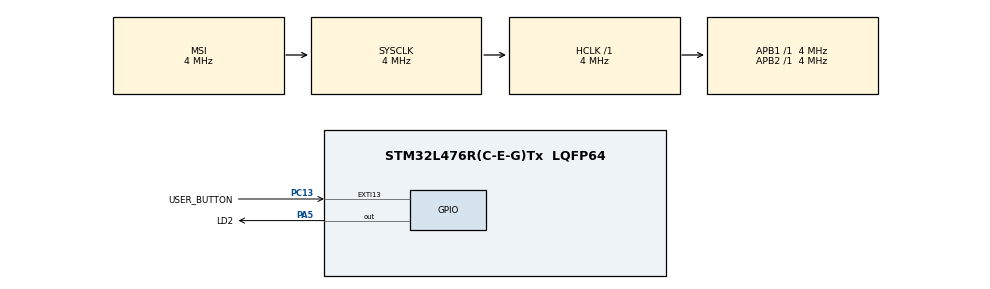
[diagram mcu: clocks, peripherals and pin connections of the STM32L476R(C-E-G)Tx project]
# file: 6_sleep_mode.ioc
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Mcu.Family=STM32L4
Mcu.Name=STM32L476R(C-E-G)Tx
Mcu.Package=LQFP64
NVIC.PriorityGroup=NVIC_PRIORITYGROUP_4
NVIC.RTC_WKUP_IRQn=true\:0\:0\:false\:false\:true\:true\:true\:true
PA13\ (JTMS-SWDIO).GPIO_Label=TMS
PA13\ (JTMS-SWDIO).Mode=Serial_Wire
PA13\ (JTMS-SWDIO).Signal=SYS_JTMS-SWDIO
PA14\ (JTCK-SWCLK).GPIO_Label=TCK
PA14\ (JTCK-SWCLK).Mode=Serial_Wire
PA14\ (JTCK-SWCLK).Signal=SYS_JTCK-SWCLK
PA3.GPIO_Mode=GPIO_MODE_AF_PP
PA3.GPIO_ModeDefaultPP=GPIO_MODE_AF_PP
PA3.GPIO_PuPd=GPIO_NOPULL
PA3.GPIO_Speed=GPIO_SPEED_FREQ_VERY_HIGH
PA3.Signal=USART2_RX
PA5.GPIO_Label=LD2
PA5.GPIO_ModeDefaultOutputPP=GPIO_MODE_OUTPUT_PP
PA5.GPIO_PuPd=GPIO_NOPULL
PA5.GPIO_Speed=GPIO_SPEED_FREQ_LOW
PA5.Signal=GPIO_Output
PB3\ (JTDO-TRACESWO).GPIO_Label=SWO
PB3\ (JTDO-TRACESWO).Signal=SYS_JTDO-SWO
PC13.GPIO_Label=USER_BUTTON
PC13.GPIO_ModeDefaultEXTI=GPIO_MODE_IT_FALLING
PC13.GPIO_PuPd=GPIO_NOPULL
PC13.Signal=GPXTI13
PC14-OSC32_IN\ (PC14).Mode=LSE-External-Oscillator
PC14-OSC32_IN\ (PC14).Signal=RCC_OSC32_IN
PC15-OSC32_OUT\ (PC15).Mode=LSE-External-Oscillator
PC15-OSC32_OUT\ (PC15).Signal=RCC_OSC32_OUT
PH0-OSC_IN\ (PH0).Signal=RCC_OSC_IN
PH1-OSC_OUT\ (PH1).Signal=RCC_OSC_OUT
ProjectManager.HeapSize=0x200
ProjectManager.StackSize=0x400
ProjectManager.TargetToolchain=STM32CubeIDE
RCC.ADCFreq_Value=64000000
RCC.AHBFreq_Value=4000000
RCC.APB1Freq_Value=4000000
RCC.APB1TimFreq_Value=4000000
RCC.APB2Freq_Value=4000000
RCC.APB2TimFreq_Value=4000000
RCC.CortexFreq_Value=4000000
RCC.HCLKFreq_Value=4000000
RCC.HSE_VALUE=8000000
RCC.HSI_VALUE=16000000
RCC.MSI_VALUE=4000000
RCC.PLLSourceVirtual=RCC_PLLSOURCE_HSI
RCC.SYSCLKFreq_VALUE=4000000
RCC.USBFreq_Value=64000000
RCC.VCOOutputFreq_Value=128000000
RTC.WakeUpClock-WakeUp=RTC_WAKEUPCLOCK_RTCCLK_DIV16
RTC.WakeUpCounter-WakeUp=20479
VP_RTC_VS_RTC_Activate.Mode=RTC_Enabled
VP_RTC_VS_RTC_WakeUp_intern.Mode=WakeUp
board=NUCLEO-L476RG

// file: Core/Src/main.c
/* USER CODE BEGIN Header */
/**
  ******************************************************************************
  * @file           : main.c
  * @brief          : Main program body
  ******************************************************************************
  * @attention
  *
  * <h2><center>&copy; Copyright (c) 2021 STMicroelectronics.
  * All rights reserved.</center></h2>
  *
  * This software component is licensed by ST under BSD 3-Clause license,
  * the "License"; You may not use this file except in compliance with the
  * License. You may obtain a copy of the License at:
  *                        opensource.org/licenses/BSD-3-Clause
  *
  ******************************************************************************
  */
/* USER CODE END Header */
#include "main.h"

RTC_HandleTypeDef hrtc;

void SystemClock_Config(void);
static void MX_GPIO_Init(void);
static void MX_RTC_Init(void);

/* USER CODE BEGIN 0 */

void start_measure(void)
{
	// rozpoczęcie "pomiaru"
	HAL_GPIO_WritePin(LD2_GPIO_Port, LD2_Pin, GPIO_PIN_SET);
}

void stop_measure(void)
{
	// zakończenie "pomiaru"
	HAL_GPIO_WritePin(LD2_GPIO_Port, LD2_Pin, GPIO_PIN_RESET);
}

void HAL_Delay(uint32_t Delay)
{
  uint32_t tickstart = HAL_GetTick();
  uint32_t wait = Delay;

  /* Add a period to guaranty minimum wait */
  if (wait < HAL_MAX_DELAY)
  {
    wait += (uint32_t)uwTickFreq;
  }

  while ((HAL_GetTick() - tickstart) < wait)
  {
	  __WFI();
  }
}

/* USER CODE END 0 */

int main(void)
{

  /* MCU Configuration--------------------------------------------------------*/

  /* Reset of all peripherals, Initializes the Flash interface and the Systick. */
  HAL_Init();

  /* Configure the system clock */
  SystemClock_Config();

  /* Initialize all configured peripherals */
  MX_GPIO_Init();
  MX_RTC_Init();
  /* USER CODE BEGIN 2 */
  start_measure();
  HAL_Delay(50);
  stop_measure();
  /* Enter the Standby mode */
  HAL_PWR_EnterSTANDBYMode();

  /* USER CODE END 2 */

  /* Infinite loop */
  while (1)
  {

  }
}

void SystemClock_Config(void)
{
  RCC_OscInitTypeDef RCC_OscInitStruct = {0};
  RCC_ClkInitTypeDef RCC_ClkInitStruct = {0};

  /** Configure the main internal regulator output voltage
  */
  if (HAL_PWREx_ControlVoltageScaling(PWR_REGULATOR_VOLTAGE_SCALE1) != HAL_OK)
  {
    Error_Handler();
  }

  /** Configure LSE Drive Capability
  */
  HAL_PWR_EnableBkUpAccess();
  __HAL_RCC_LSEDRIVE_CONFIG(RCC_LSEDRIVE_LOW);

  /** Initializes the RCC Oscillators according to the specified parameters
  * in the RCC_OscInitTypeDef structure.
  */
  RCC_OscInitStruct.OscillatorType = RCC_OSCILLATORTYPE_LSI|RCC_OSCILLATORTYPE_LSE
                              |RCC_OSCILLATORTYPE_MSI;
  RCC_OscInitStruct.LSEState = RCC_LSE_ON;
  RCC_OscInitStruct.LSIState = RCC_LSI_ON;
  RCC_OscInitStruct.MSIState = RCC_MSI_ON;
  RCC_OscInitStruct.MSICalibrationValue = 0;
  RCC_OscInitStruct.MSIClockRange = RCC_MSIRANGE_6;
  RCC_OscInitStruct.PLL.PLLState = RCC_PLL_NONE;
  if (HAL_RCC_OscConfig(&RCC_OscInitStruct) != HAL_OK)
  {
    Error_Handler();
  }

  /** Initializes the CPU, AHB and APB buses clocks
  */
  RCC_ClkInitStruct.ClockType = RCC_CLOCKTYPE_HCLK|RCC_CLOCKTYPE_SYSCLK
                              |RCC_CLOCKTYPE_PCLK1|RCC_CLOCKTYPE_PCLK2;
  RCC_ClkInitStruct.SYSCLKSource = RCC_SYSCLKSOURCE_MSI;
  RCC_ClkInitStruct.AHBCLKDivider = RCC_SYSCLK_DIV1;
  RCC_ClkInitStruct.APB1CLKDivider = RCC_HCLK_DIV1;
  RCC_ClkInitStruct.APB2CLKDivider = RCC_HCLK_DIV1;

  if (HAL_RCC_ClockConfig(&RCC_ClkInitStruct, FLASH_LATENCY_0) != HAL_OK)
  {
    Error_Handler();
  }

  /** Enable MSI Auto calibration
  */
  HAL_RCCEx_EnableMSIPLLMode();
}

static void MX_RTC_Init(void)
{

  /** Initialize RTC Only
  */
  hrtc.Instance = RTC;
  hrtc.Init.HourFormat = RTC_HOURFORMAT_24;
  hrtc.Init.AsynchPrediv = 127;
  hrtc.Init.SynchPrediv = 255;
  hrtc.Init.OutPut = RTC_OUTPUT_DISABLE;
  hrtc.Init.OutPutRemap = RTC_OUTPUT_REMAP_NONE;
  hrtc.Init.OutPutPolarity = RTC_OUTPUT_POLARITY_HIGH;
  hrtc.Init.OutPutType = RTC_OUTPUT_TYPE_OPENDRAIN;
  if (HAL_RTC_Init(&hrtc) != HAL_OK)
  {
    Error_Handler();
  }
  /** Enable the WakeUp
  */
  if (HAL_RTCEx_SetWakeUpTimer_IT(&hrtc, 2047, RTC_WAKEUPCLOCK_RTCCLK_DIV16) != HAL_OK)
  {
    Error_Handler();
  }

}

static void MX_GPIO_Init(void)
{
  GPIO_InitTypeDef GPIO_InitStruct = {0};

  /* GPIO Ports Clock Enable */
  __HAL_RCC_GPIOC_CLK_ENABLE();
  __HAL_RCC_GPIOH_CLK_ENABLE();
  __HAL_RCC_GPIOA_CLK_ENABLE();
  __HAL_RCC_GPIOB_CLK_ENABLE();

  /*Configure GPIO pin Output Level */
  HAL_GPIO_WritePin(LD2_GPIO_Port, LD2_Pin, GPIO_PIN_RESET);

  /*Configure GPIO pin : USER_BUTTON_Pin */
  GPIO_InitStruct.Pin = USER_BUTTON_Pin;
  GPIO_InitStruct.Mode = GPIO_MODE_IT_FALLING;
  GPIO_InitStruct.Pull = GPIO_NOPULL;
  HAL_GPIO_Init(USER_BUTTON_GPIO_Port, &GPIO_InitStruct);

  /*Configure GPIO pin : PA3 */
  GPIO_InitStruct.Pin = GPIO_PIN_3;
  GPIO_InitStruct.Mode = GPIO_MODE_AF_PP;
  GPIO_InitStruct.Pull = GPIO_NOPULL;
  GPIO_InitStruct.Speed = GPIO_SPEED_FREQ_VERY_HIGH;
  GPIO_InitStruct.Alternate = GPIO_AF7_USART2;
  HAL_GPIO_Init(GPIOA, &GPIO_InitStruct);

  /*Configure GPIO pin : LD2_Pin */
  GPIO_InitStruct.Pin = LD2_Pin;
  GPIO_InitStruct.Mode = GPIO_MODE_OUTPUT_PP;
  GPIO_InitStruct.Pull = GPIO_NOPULL;
  GPIO_InitStruct.Speed = GPIO_SPEED_FREQ_LOW;
  HAL_GPIO_Init(LD2_GPIO_Port, &GPIO_InitStruct);

}

void Error_Handler(void)
{
  __disable_irq();
  while (1)
  {
  }
}
